# fcr_me13 register map
Registers are read-write, no defined reset value unless marked. A register's access mark holds for its fields unless they carry their own. Offsets are from the block's base; lines under a group give offsets from that group; [hi:lo] are bit positions; {n}, {i} and the like mark numbered series; 'fields as' and 'values as' point back to an identical list; <NAME> marks a mode.

## Memory map
0x40000800 FCR size 0x400 — Function Control Register.

## FCR — Function Control Register.
Base 0x40000800
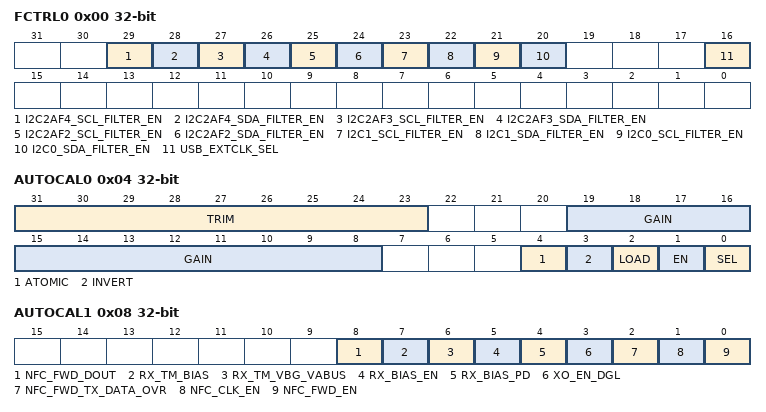
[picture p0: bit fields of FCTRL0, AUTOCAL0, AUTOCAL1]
0x00 FCTRL0 — Register 0.
  [29] I2C2AF4_SCL_FILTER_EN — I2C2 AF4 SCL Glitch Filter Enable
    0=dis (Filter disabled.); 1=en (Filter enabled.)
  [28] I2C2AF4_SDA_FILTER_EN — I2C2 AF4 SDA Glitch Filter Enable
    0=dis (Filter disabled.); 1=en (Filter enabled.)
  [27] I2C2AF3_SCL_FILTER_EN — I2C2 AF3 SCL Glitch Filter Enable.
    0=dis (Filter disabled.); 1=en (Filter enabled.)
  [26] I2C2AF3_SDA_FILTER_EN — I2C2 AF3 SDA Glitch Filter Enable.
    0=dis (Filter disabled.); 1=en (Filter enabled.)
  [25] I2C2AF2_SCL_FILTER_EN — I2C2 AF2 SCL Glitch Filter Enable.
    0=dis (Filter disabled.); 1=en (Filter enabled.)
  [24] I2C2AF2_SDA_FILTER_EN — I2C2 AF2 SDA Glitch Filter Enable.
    0=dis (Filter disabled.); 1=en (Filter enabled.)
  [23] I2C1_SCL_FILTER_EN — I2C1 SCL Glitch Filter Enable.
    0=dis (Filter disabled.); 1=en (Filter enabled.)
  [22] I2C1_SDA_FILTER_EN — I2C1 SDA Glitch Filter Enable.
    0=dis (Filter disabled.); 1=en (Filter enabled.)
  [21] I2C0_SCL_FILTER_EN — I2C0 SCL Glitch Filter Enable.
    0=dis (Filter disabled.); 1=en (Filter enabled.)
  [20] I2C0_SDA_FILTER_EN — I2C0 SDA Glitch Filter Enable.
    0=dis (Filter disabled.); 1=en (Filter enabled.)
  [16] USB_EXTCLK_SEL — USB External Core Clock Select.
    0=sys (Generated clock from system clock.); 1=dig (Digital clock from a GPIO.)
0x04 AUTOCAL0 — Register 1.
  [31:23] TRIM — 150MHz HFIO Auto Calibration Trim
  [19:8] GAIN — MU value.
  [4] ATOMIC — Atomic mode.
    0=not (Not Running.); 1=run (Running.)
  [3] INVERT — Invert Gain.
    0=not (Not Running.); 1=run (Running.)
  [2] LOAD — Load Trim.
  [1] EN — Autocalibration Run.
    0=not (Not Running.); 1=run (Running.)
  [0] SEL — Auto-calibration Enable.
    0=dis (Disabled.); 1=en (Enabled.)
0x08 AUTOCAL1 — Register 2.
  [8] NFC_FWD_DOUT — FWD output from FNC block
  [7] RX_TM_BIAS
  [6] RX_TM_VBG_VABUS
  [5] RX_BIAS_EN — Enable the NFC receiver analog blocks
  [4] RX_BIAS_PD — Power down enable for NFC receiver analog block
  [3] XO_EN_DGL
  [2] NFC_FWD_TX_DATA_OVR — FWD input for NFC block
  [1] NFC_CLK_EN — Enabled the NFC blocks clock divider in Analog
  [0] NFC_FWD_EN — Enabled FWD mode for NFC block
0x0C AUTOCAL2 — Register 3.
  [7:0] RUNTIME — Automatic Calibration Run Time.
